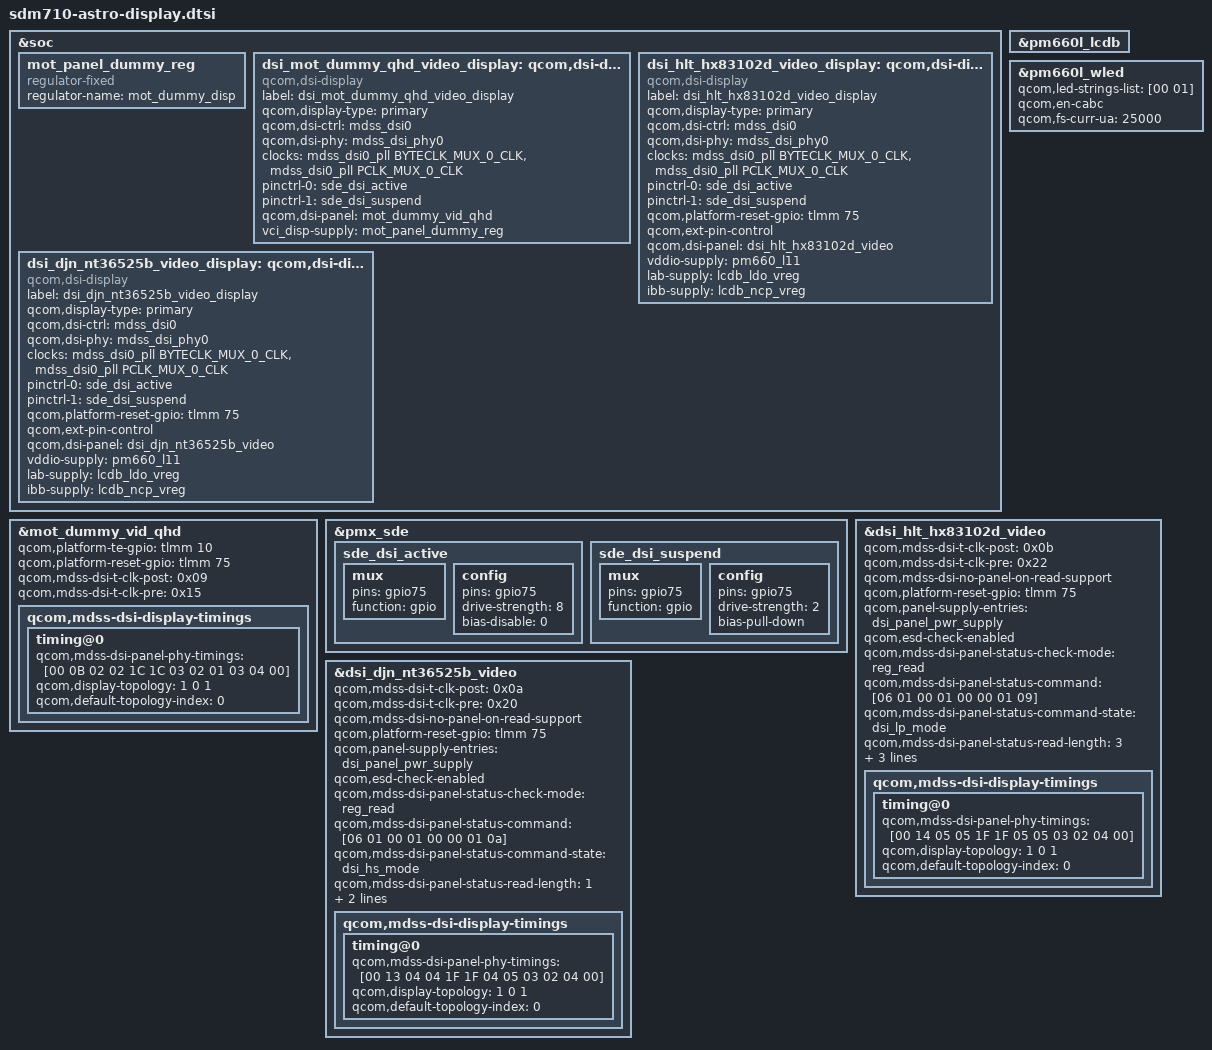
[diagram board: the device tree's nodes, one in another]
/* Copyright (c) 2019, The Linux Foundation. All rights reserved.
 *
 * This program is free software; you can redistribute it and/or modify
 * it under the terms of the GNU General Public License version 2 and
 * only version 2 as published by the Free Software Foundation.
 *
 * This program is distributed in the hope that it will be useful,
 * but WITHOUT ANY WARRANTY; without even the implied warranty of
 * MERCHANTABILITY or FITNESS FOR A PARTICULAR PURPOSE.  See the
 * GNU General Public License for more details.
 */
#include "dsi-panel-mot-dummy-qhd-video.dtsi"
#include "dsi-panel-moto-hx83102d-hlt-hdplus-video.dtsi"
#include "dsi-panel-mot-nt36525b-djn-hdplus-video.dtsi"
#include "pm660a.dtsi"

&soc {
	mot_panel_dummy_reg: mot_panel_dummy_reg {
		compatible = "regulator-fixed";
		regulator-name = "mot_dummy_disp";
	};


	dsi_mot_dummy_qhd_video_display: qcom,dsi-display@19 {
		compatible = "qcom,dsi-display";
		label = "dsi_mot_dummy_qhd_video_display";
		qcom,display-type = "primary";

		qcom,dsi-ctrl = <&mdss_dsi0>;
		qcom,dsi-phy = <&mdss_dsi_phy0>;
		clocks = <&mdss_dsi0_pll BYTECLK_MUX_0_CLK>,
			<&mdss_dsi0_pll PCLK_MUX_0_CLK>;
		clock-names = "mux_byte_clk", "mux_pixel_clk";

		pinctrl-names = "panel_active", "panel_suspend";
		pinctrl-0 = <&sde_dsi_active>;
		pinctrl-1 = <&sde_dsi_suspend>;

		qcom,dsi-panel = <&mot_dummy_vid_qhd>;
		vci_disp-supply = <&mot_panel_dummy_reg>;
	};

};

&mot_dummy_vid_qhd {
	qcom,platform-te-gpio = <&tlmm 10 0>;
	qcom,platform-reset-gpio = <&tlmm 75 0>;
	qcom,mdss-dsi-t-clk-post = <0x09>;
	qcom,mdss-dsi-t-clk-pre = <0x15>;
	qcom,mdss-dsi-display-timings {
		timing@0{
			qcom,mdss-dsi-panel-phy-timings = [00 0B 02 02 1C 1C 03
							02 01 03 04 00];
			qcom,display-topology = <1 0 1>;
			qcom,default-topology-index = <0>;
		};
	};
};

&pm660l_lcdb {
        status = "ok";
};

&pm660l_wled {
       status = "ok";
       qcom,led-strings-list = [00 01];
       qcom,en-cabc;
       qcom,fs-curr-ua = <25000>;
};

&pmx_sde{
	sde_dsi_active: sde_dsi_active {
		mux {
			pins = "gpio75";
			function = "gpio";
		};

		config {
			pins = "gpio75";
			drive-strength = <8>;   /* 8 mA */
			bias-disable = <0>;   /* no pull */
		};
	};
	sde_dsi_suspend: sde_dsi_suspend {
		mux {
			pins = "gpio75";
			function = "gpio";
		};

		config {
			pins = "gpio75";
			drive-strength = <2>;   /* 2 mA */
			bias-pull-down;         /* PULL DOWN */
		};
	};
};

&soc {
	dsi_hlt_hx83102d_video_display: qcom,dsi-display@21{
		compatible = "qcom,dsi-display";
		label = "dsi_hlt_hx83102d_video_display";
		qcom,display-type = "primary";
		qcom,dsi-ctrl = <&mdss_dsi0>;
		qcom,dsi-phy = <&mdss_dsi_phy0>;
		clocks = <&mdss_dsi0_pll BYTECLK_MUX_0_CLK>,
			 <&mdss_dsi0_pll PCLK_MUX_0_CLK>;
		clock-names = "mux_byte_clk", "mux_pixel_clk";
		pinctrl-names = "panel_active", "panel_suspend";
		pinctrl-0 = <&sde_dsi_active>;
		pinctrl-1 = <&sde_dsi_suspend>;
		qcom,platform-reset-gpio = <&tlmm 75 0>;
		qcom,ext-pin-control;
		qcom,dsi-panel = <&dsi_hlt_hx83102d_video>;
		vddio-supply = <&pm660_l11>;
		lab-supply = <&lcdb_ldo_vreg>;
		ibb-supply = <&lcdb_ncp_vreg>;
	};
	dsi_djn_nt36525b_video_display: qcom,dsi-display@22{
		compatible = "qcom,dsi-display";
		label = "dsi_djn_nt36525b_video_display";
		qcom,display-type = "primary";
		qcom,dsi-ctrl = <&mdss_dsi0>;
		qcom,dsi-phy = <&mdss_dsi_phy0>;
		clocks = <&mdss_dsi0_pll BYTECLK_MUX_0_CLK>,
			 <&mdss_dsi0_pll PCLK_MUX_0_CLK>;
		clock-names = "mux_byte_clk", "mux_pixel_clk";
		pinctrl-names = "panel_active", "panel_suspend";
		pinctrl-0 = <&sde_dsi_active>;
		pinctrl-1 = <&sde_dsi_suspend>;
		qcom,platform-reset-gpio = <&tlmm 75 0>;
		qcom,ext-pin-control;
		qcom,dsi-panel = <&dsi_djn_nt36525b_video>;
		vddio-supply = <&pm660_l11>;
		lab-supply = <&lcdb_ldo_vreg>;
		ibb-supply = <&lcdb_ncp_vreg>;
	};
};

&dsi_hlt_hx83102d_video {
        qcom,mdss-dsi-t-clk-post = <0x0b>;
        qcom,mdss-dsi-t-clk-pre = <0x22>;
	qcom,mdss-dsi-no-panel-on-read-support;
        qcom,mdss-dsi-display-timings {
                timing@0{
                        qcom,mdss-dsi-panel-phy-timings = [00 14 05 05 1F 1F 05 05 03 02 04 00];
                        qcom,display-topology = <1 0 1>;
                        qcom,default-topology-index = <0>;
                };
        };
};

&dsi_djn_nt36525b_video {
        qcom,mdss-dsi-t-clk-post = <0x0a>;
        qcom,mdss-dsi-t-clk-pre = <0x20>;
	qcom,mdss-dsi-no-panel-on-read-support;
        qcom,mdss-dsi-display-timings {
                timing@0{
                        qcom,mdss-dsi-panel-phy-timings = [00 13 04 04 1F 1F 04 05 03 02 04 00];
                        qcom,display-topology = <1 0 1>;
                        qcom,default-topology-index = <0>;
                };
        };
};
&dsi_hlt_hx83102d_video {
	qcom,platform-reset-gpio = <&tlmm 75 0>;
	qcom,panel-supply-entries = <&dsi_panel_pwr_supply>;
};
&dsi_djn_nt36525b_video {
	qcom,platform-reset-gpio = <&tlmm 75 0>;
	qcom,panel-supply-entries = <&dsi_panel_pwr_supply>;
};

&dsi_hlt_hx83102d_video {
        qcom,esd-check-enabled;
        qcom,mdss-dsi-panel-status-check-mode = "reg_read";
        qcom,mdss-dsi-panel-status-command =[06 01 00 01 00 00 01 09];
        qcom,mdss-dsi-panel-status-command-state = "dsi_lp_mode";
        qcom,mdss-dsi-panel-status-read-length = <3>;
        qcom,mdss-dsi-panel-max-error-count = <3>;
        qcom,mdss-dsi-panel-status-value = <0x80 0x73 0x04>;
};

&dsi_djn_nt36525b_video {
        qcom,esd-check-enabled;
        qcom,mdss-dsi-panel-status-check-mode = "reg_read";
        qcom,mdss-dsi-panel-status-command =[06 01 00 01 00 00 01 0a];
        qcom,mdss-dsi-panel-status-command-state = "dsi_hs_mode";
        qcom,mdss-dsi-panel-status-read-length = <1>;
        qcom,mdss-dsi-panel-max-error-count = <3>;
        qcom,mdss-dsi-panel-status-value = <0x9c>;
};
